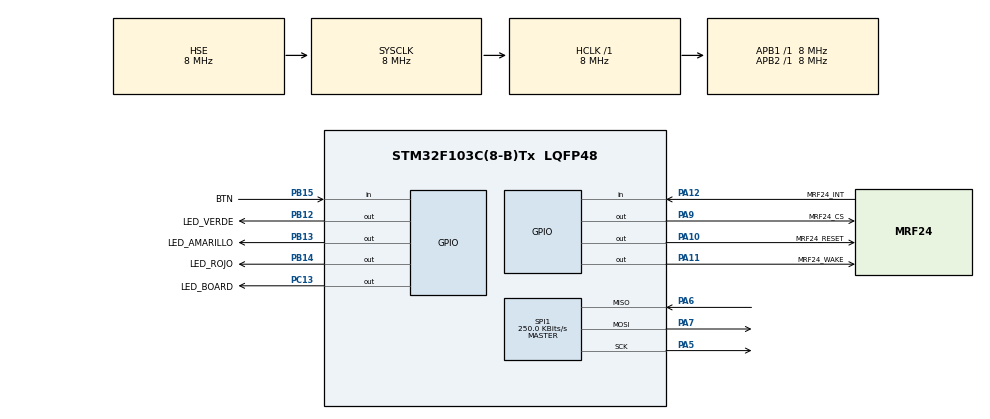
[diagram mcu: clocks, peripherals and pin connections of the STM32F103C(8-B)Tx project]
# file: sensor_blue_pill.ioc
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Mcu.Family=STM32F1
Mcu.Name=STM32F103C(8-B)Tx
Mcu.Package=LQFP48
NVIC.PriorityGroup=NVIC_PRIORITYGROUP_4
PA10.GPIO_Label=MRF24_RESET
PA10.Signal=GPIO_Output
PA11.GPIO_Label=MRF24_WAKE
PA11.Signal=GPIO_Output
PA12.GPIO_Label=MRF24_INT
PA12.Signal=GPIO_Input
PA13.Mode=Serial_Wire
PA13.Signal=SYS_JTMS-SWDIO
PA14.Mode=Serial_Wire
PA14.Signal=SYS_JTCK-SWCLK
PA5.GPIO_Speed=GPIO_SPEED_FREQ_MEDIUM
PA5.Mode=Full_Duplex_Master
PA5.Signal=SPI1_SCK
PA6.Mode=Full_Duplex_Master
PA6.Signal=SPI1_MISO
PA7.GPIO_Speed=GPIO_SPEED_FREQ_MEDIUM
PA7.Mode=Full_Duplex_Master
PA7.Signal=SPI1_MOSI
PA9.GPIO_Label=MRF24_CS
PA9.Signal=GPIO_Output
PB12.GPIO_Label=LED_VERDE
PB12.Signal=GPIO_Output
PB13.GPIO_Label=LED_AMARILLO
PB13.Signal=GPIO_Output
PB14.GPIO_Label=LED_ROJO
PB14.Signal=GPIO_Output
PB15.GPIO_Label=BTN
PB15.GPIO_PuPd=GPIO_PULLDOWN
PB15.Signal=GPIO_Input
PC13-TAMPER-RTC.GPIO_Label=LED_BOARD
PC13-TAMPER-RTC.PinState=GPIO_PIN_SET
PC13-TAMPER-RTC.Signal=GPIO_Output
PC14-OSC32_IN.Mode=LSE-External-Oscillator
PC14-OSC32_IN.Signal=RCC_OSC32_IN
PC15-OSC32_OUT.Mode=LSE-External-Oscillator
PC15-OSC32_OUT.Signal=RCC_OSC32_OUT
PD0-OSC_IN.Mode=HSE-External-Oscillator
PD0-OSC_IN.Signal=RCC_OSC_IN
PD1-OSC_OUT.Mode=HSE-External-Oscillator
PD1-OSC_OUT.Signal=RCC_OSC_OUT
ProjectManager.HeapSize=0x200
ProjectManager.StackSize=0x400
ProjectManager.TargetToolchain=STM32CubeIDE
RCC.AHBFreq_Value=8000000
RCC.APB1Freq_Value=8000000
RCC.APB1TimFreq_Value=8000000
RCC.APB2Freq_Value=8000000
RCC.APB2TimFreq_Value=8000000
RCC.HCLKFreq_Value=8000000
RCC.PLLSourceVirtual=RCC_PLLSOURCE_HSE
RCC.SYSCLKFreq_VALUE=8000000
RCC.SYSCLKSource=RCC_SYSCLKSOURCE_HSE
RCC.USBFreq_Value=16000000
SPI1.BaudRatePrescaler=SPI_BAUDRATEPRESCALER_32
SPI1.CLKPolarity=SPI_POLARITY_LOW
SPI1.CRCCalculation=SPI_CRCCALCULATION_DISABLE
SPI1.CalculateBaudRate=250.0 KBits/s
SPI1.Direction=SPI_DIRECTION_2LINES
SPI1.FirstBit=SPI_FIRSTBIT_MSB
SPI1.Mode=SPI_MODE_MASTER
SPI1.VirtualType=VM_MASTER
board=custom

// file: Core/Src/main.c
/* USER CODE BEGIN Header */
/**
  ******************************************************************************
  * @file           : main.c
  * @brief          : Main program body
  ******************************************************************************
  * @attention
  *
  * Copyright (c) 2025 STMicroelectronics.
  * All rights reserved.
  *
  * This software is licensed under terms that can be found in the LICENSE file
  * in the root directory of this software component.
  * If no LICENSE file comes with this software, it is provided AS-IS.
  *
  ******************************************************************************
  */
/* USER CODE END Header */
#include "main.h"

/* USER CODE BEGIN Includes */
#include "app_principal.h"
#include "app_leds.h"
/* USER CODE END Includes */

SPI_HandleTypeDef hspi1;

void SystemClock_Config(void);
static void MX_GPIO_Init(void);
static void MX_SPI1_Init(void);

int main(void)
{

  /* MCU Configuration--------------------------------------------------------*/

  /* Reset of all peripherals, Initializes the Flash interface and the Systick. */
  HAL_Init();

  /* Configure the system clock */
  SystemClock_Config();

  /* Initialize all configured peripherals */
  MX_GPIO_Init();
  MX_SPI1_Init();
  /* USER CODE BEGIN 2 */
  bucle();

  /* USER CODE END 2 */

  /* Infinite loop */
  while (1)
  {

  }
}

void SystemClock_Config(void)
{
  RCC_OscInitTypeDef RCC_OscInitStruct = {0};
  RCC_ClkInitTypeDef RCC_ClkInitStruct = {0};

  /** Initializes the RCC Oscillators according to the specified parameters
  * in the RCC_OscInitTypeDef structure.
  */
  RCC_OscInitStruct.OscillatorType = RCC_OSCILLATORTYPE_HSE;
  RCC_OscInitStruct.HSEState = RCC_HSE_ON;
  RCC_OscInitStruct.PLL.PLLState = RCC_PLL_NONE;
  if (HAL_RCC_OscConfig(&RCC_OscInitStruct) != HAL_OK)
  {
    Error_Handler();
  }

  /** Initializes the CPU, AHB and APB buses clocks
  */
  RCC_ClkInitStruct.ClockType = RCC_CLOCKTYPE_HCLK|RCC_CLOCKTYPE_SYSCLK
                              |RCC_CLOCKTYPE_PCLK1|RCC_CLOCKTYPE_PCLK2;
  RCC_ClkInitStruct.SYSCLKSource = RCC_SYSCLKSOURCE_HSE;
  RCC_ClkInitStruct.AHBCLKDivider = RCC_SYSCLK_DIV1;
  RCC_ClkInitStruct.APB1CLKDivider = RCC_HCLK_DIV1;
  RCC_ClkInitStruct.APB2CLKDivider = RCC_HCLK_DIV1;

  if (HAL_RCC_ClockConfig(&RCC_ClkInitStruct, FLASH_LATENCY_0) != HAL_OK)
  {
    Error_Handler();
  }
}

static void MX_SPI1_Init(void)
{

  /* SPI1 parameter configuration*/
  hspi1.Instance = SPI1;
  hspi1.Init.Mode = SPI_MODE_MASTER;
  hspi1.Init.Direction = SPI_DIRECTION_2LINES;
  hspi1.Init.DataSize = SPI_DATASIZE_8BIT;
  hspi1.Init.CLKPolarity = SPI_POLARITY_LOW;
  hspi1.Init.CLKPhase = SPI_PHASE_1EDGE;
  hspi1.Init.NSS = SPI_NSS_SOFT;
  hspi1.Init.BaudRatePrescaler = SPI_BAUDRATEPRESCALER_32;
  hspi1.Init.FirstBit = SPI_FIRSTBIT_MSB;
  hspi1.Init.TIMode = SPI_TIMODE_DISABLE;
  hspi1.Init.CRCCalculation = SPI_CRCCALCULATION_DISABLE;
  hspi1.Init.CRCPolynomial = 10;
  if (HAL_SPI_Init(&hspi1) != HAL_OK)
  {
    Error_Handler();
  }

}

static void MX_GPIO_Init(void)
{
  GPIO_InitTypeDef GPIO_InitStruct = {0};

  /* GPIO Ports Clock Enable */
  __HAL_RCC_GPIOC_CLK_ENABLE();
  __HAL_RCC_GPIOD_CLK_ENABLE();
  __HAL_RCC_GPIOA_CLK_ENABLE();
  __HAL_RCC_GPIOB_CLK_ENABLE();

  /*Configure GPIO pin Output Level */
  HAL_GPIO_WritePin(LED_BOARD_GPIO_Port, LED_BOARD_Pin, GPIO_PIN_SET);

  /*Configure GPIO pin Output Level */
  HAL_GPIO_WritePin(GPIOB, LED_VERDE_Pin|LED_AMARILLO_Pin|LED_ROJO_Pin, GPIO_PIN_RESET);

  /*Configure GPIO pin Output Level */
  HAL_GPIO_WritePin(GPIOA, MRF24_CS_Pin|MRF24_RESET_Pin|MRF24_WAKE_Pin, GPIO_PIN_RESET);

  /*Configure GPIO pin : LED_BOARD_Pin */
  GPIO_InitStruct.Pin = LED_BOARD_Pin;
  GPIO_InitStruct.Mode = GPIO_MODE_OUTPUT_PP;
  GPIO_InitStruct.Pull = GPIO_NOPULL;
  GPIO_InitStruct.Speed = GPIO_SPEED_FREQ_LOW;
  HAL_GPIO_Init(LED_BOARD_GPIO_Port, &GPIO_InitStruct);

  /*Configure GPIO pins : LED_VERDE_Pin LED_AMARILLO_Pin LED_ROJO_Pin */
  GPIO_InitStruct.Pin = LED_VERDE_Pin|LED_AMARILLO_Pin|LED_ROJO_Pin;
  GPIO_InitStruct.Mode = GPIO_MODE_OUTPUT_PP;
  GPIO_InitStruct.Pull = GPIO_NOPULL;
  GPIO_InitStruct.Speed = GPIO_SPEED_FREQ_LOW;
  HAL_GPIO_Init(GPIOB, &GPIO_InitStruct);

  /*Configure GPIO pin : BTN_Pin */
  GPIO_InitStruct.Pin = BTN_Pin;
  GPIO_InitStruct.Mode = GPIO_MODE_INPUT;
  GPIO_InitStruct.Pull = GPIO_PULLDOWN;
  HAL_GPIO_Init(BTN_GPIO_Port, &GPIO_InitStruct);

  /*Configure GPIO pins : MRF24_CS_Pin MRF24_RESET_Pin MRF24_WAKE_Pin */
  GPIO_InitStruct.Pin = MRF24_CS_Pin|MRF24_RESET_Pin|MRF24_WAKE_Pin;
  GPIO_InitStruct.Mode = GPIO_MODE_OUTPUT_PP;
  GPIO_InitStruct.Pull = GPIO_NOPULL;
  GPIO_InitStruct.Speed = GPIO_SPEED_FREQ_LOW;
  HAL_GPIO_Init(GPIOA, &GPIO_InitStruct);

  /*Configure GPIO pin : MRF24_INT_Pin */
  GPIO_InitStruct.Pin = MRF24_INT_Pin;
  GPIO_InitStruct.Mode = GPIO_MODE_INPUT;
  GPIO_InitStruct.Pull = GPIO_NOPULL;
  HAL_GPIO_Init(MRF24_INT_GPIO_Port, &GPIO_InitStruct);

}

void Error_Handler(void)
{
  /* USER CODE BEGIN Error_Handler_Debug */
  /* User can add his own implementation to report the HAL error return state */
  __disable_irq();
  while (1)
  {
	  HAL_GPIO_WritePin(LED_BOARD_GPIO_Port, LED_BOARD_Pin, LED_PRENDIDO);
	  HAL_GPIO_WritePin(LED_VERDE_GPIO_Port, LED_VERDE_Pin, LED_APAGADO);
	  HAL_GPIO_WritePin(LED_AMARILLO_GPIO_Port, LED_AMARILLO_Pin, LED_APAGADO);
	  HAL_GPIO_WritePin(LED_ROJO_GPIO_Port, LED_ROJO_Pin, LED_APAGADO);
  }
  /* USER CODE END Error_Handler_Debug */
}
